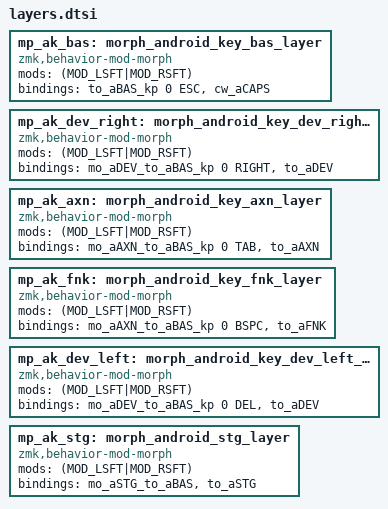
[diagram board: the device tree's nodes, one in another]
// tap:      escape      
// long-tap: to BAS layer
// shift:    caps lock
mp_ak_bas: morph_android_key_bas_layer {
    compatible = "zmk,behavior-mod-morph";
    #binding-cells = <0>;
    mods = <(MOD_LSFT|MOD_RSFT)>;
    bindings = <&to_aBAS_kp 0 ESC>, <&cw_aCAPS>;
};

// tap:      right arrow       
// long-tap: to DEV momentary
// shift:    to DEV layer
mp_ak_dev_right: morph_android_key_dev_right_layer {
    compatible = "zmk,behavior-mod-morph";
    #binding-cells = <0>;
    mods = <(MOD_LSFT|MOD_RSFT)>;
    bindings = <&mo_aDEV_to_aBAS_kp 0 RIGHT>, <&to_aDEV>;
};

// tap:      tab       
// long-tap: to AXN momentary
// shift:    to AXN layer
mp_ak_axn: morph_android_key_axn_layer {
    compatible = "zmk,behavior-mod-morph";
    #binding-cells = <0>;
    mods = <(MOD_LSFT|MOD_RSFT)>;
    bindings = <&mo_aAXN_to_aBAS_kp 0 TAB>, <&to_aAXN>;
};

// tap:      backspace       
// long-tap: to AXN momentary
// shift:    to FNK layer
mp_ak_fnk: morph_android_key_fnk_layer {
    compatible = "zmk,behavior-mod-morph";
    #binding-cells = <0>;
    mods = <(MOD_LSFT|MOD_RSFT)>;
    bindings = <&mo_aAXN_to_aBAS_kp 0 BSPC>, <&to_aFNK>;
};

// tap:      delete    
// long-tap: to DEV momentary
// shift:    to DEV layer
mp_ak_dev_left: morph_android_key_dev_left_layer {
    compatible = "zmk,behavior-mod-morph";
    #binding-cells = <0>;
    mods = <(MOD_LSFT|MOD_RSFT)>;
    bindings = <&mo_aDEV_to_aBAS_kp 0 DEL>, <&to_aDEV>;
};

// long-tap: to STG momentary
// shift:    to STG layer
mp_ak_stg: morph_android_stg_layer {
    compatible = "zmk,behavior-mod-morph";
    #binding-cells = <0>;
    mods = <(MOD_LSFT|MOD_RSFT)>;
    bindings = <&mo_aSTG_to_aBAS>, <&to_aSTG>;
};

